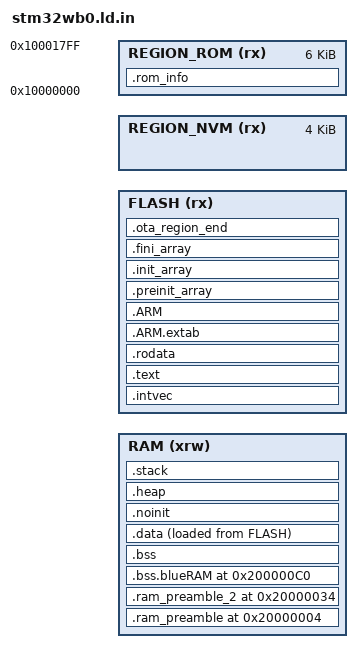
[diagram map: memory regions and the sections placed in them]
ENTRY(Reset_Handler)

_Min_Heap_Size = @min_heap_size@;
_Min_Stack_Size = @min_stack_size@;

_MEMORY_RAM_BEGIN_ = @ram_origin@;
_MEMORY_RAM_SIZE_ = @ram_length@;
_MEMORY_FLASH_BEGIN_ = @flash_origin@;
_MEMORY_FLASH_SIZE_ = @flash_length@;
_MEMORY_ROM_BEGIN_ = 0x10000000;
_MEMORY_ROM_SIZE_ = 0x1800;
FLASH_NVM_DATASIZE = 4K;

MEMORY
{
  RAM (xrw)       : ORIGIN = _MEMORY_RAM_BEGIN_, LENGTH = _MEMORY_RAM_SIZE_
  FLASH (rx)      : ORIGIN = _MEMORY_FLASH_BEGIN_, LENGTH = _MEMORY_FLASH_SIZE_ - FLASH_NVM_DATASIZE
  REGION_NVM (rx) : ORIGIN = _MEMORY_FLASH_BEGIN_ + _MEMORY_FLASH_SIZE_ - FLASH_NVM_DATASIZE, LENGTH = FLASH_NVM_DATASIZE
  REGION_ROM (rx) : ORIGIN = _MEMORY_ROM_BEGIN_, LENGTH = _MEMORY_ROM_SIZE_
}

SECTIONS
{
  .intvec (ORIGIN(FLASH)) :
  {
    . = ALIGN(4);
    KEEP(*(.intvec))
    . = ALIGN(4);
  } >FLASH

  .text :
  {
    . = ALIGN(4);
    KEEP(*(TAG_OTA_START))
    *(.text)
    *(.text*)
    *(.glue_7)
    *(.glue_7t)
    *(.eh_frame)
    KEEP(*(.cmd_call_table))
    KEEP(*(.init))
    KEEP(*(.fini))
    . = ALIGN(4);
    _etext = .;
  } >FLASH

  .rodata :
  {
    . = ALIGN(4);
    *(.rodata)
    *(.rodata*)
    . = ALIGN(4);
  } >FLASH

  .ARM.extab : { *(.ARM.extab* .gnu.linkonce.armextab.*) } >FLASH
  .ARM :
  {
    __exidx_start = .;
    *(.ARM.exidx*)
    __exidx_end = .;
  } >FLASH

  .preinit_array :
  {
    PROVIDE_HIDDEN (__preinit_array_start = .);
    KEEP (*(.preinit_array*))
    PROVIDE_HIDDEN (__preinit_array_end = .);
  } >FLASH
  .init_array :
  {
    PROVIDE_HIDDEN (__init_array_start = .);
    KEEP (*(SORT(.init_array.*)))
    KEEP (*(.init_array*))
    PROVIDE_HIDDEN (__init_array_end = .);
  } >FLASH
  .fini_array :
  {
    PROVIDE_HIDDEN (__fini_array_start = .);
    KEEP (*(SORT(.fini_array.*)))
    KEEP (*(.fini_array*))
    PROVIDE_HIDDEN (__fini_array_end = .);
  } >FLASH

  _sidata = LOADADDR(.data);

  .ram_preamble 0x20000004 (NOLOAD) :
  {
    KEEP(*(.ram_vr))
  } >RAM

  .ram_preamble_2 0x20000034 (NOLOAD) :
  {
    KEEP(*(.crash_info_ram_vr))
  } >RAM

  .bss.blueRAM 0x200000C0 :
  {
    . = ALIGN(4);
    _sbssblue = .;
    KEEP(*(.bss.__blue_RAM))
    . = ALIGN(4);
    _ebssblue = .;
  } >RAM

  .bss :
  {
    . = ALIGN(4);
    _sbss = .;
    __bss_start__ = _sbss;
    *(.bss)
    *(.bss*)
    *(COMMON)
    . = ALIGN(4);
    _ebss = .;
    __bss_end__ = _ebss;
  } >RAM

  .data :
  {
    . = ALIGN(4);
    _sdata = .;
    *(.data)
    *(.data*)
    . = ALIGN(4);
    _edata = .;
  } >RAM AT> FLASH

  .noinit (NOLOAD) :
  {
    . = ALIGN(4);
    *(.noinit)
    *(.noinit*)
    . = ALIGN(4);
  } >RAM

  .ota_region_end :
  {
    . = ALIGN(4);
    KEEP(*(TAG_OTA_END))
    . = ALIGN(4);
  } >FLASH

  .heap (NOLOAD) :
  {
    . = ALIGN(4);
    PROVIDE ( end = . );
    PROVIDE ( _end = . );
    . = . + _Min_Heap_Size;
    . = ALIGN(4);
  } >RAM

  .stack (ORIGIN(RAM) + LENGTH(RAM) - _Min_Stack_Size) (NOLOAD) :
  {
    . = ALIGN(4);
    . = . + _Min_Stack_Size;
    . = ALIGN(4);
    _estack = .;
  } >RAM

  .rom_info (NOLOAD) :
  {
    . = ALIGN(4);
    KEEP(*(.rom_info))
    . = ALIGN(4);
  } >REGION_ROM

  /DISCARD/ :
  {
    libc.a ( * )
    libm.a ( * )
    libgcc.a ( * )
  }

  .ARM.attributes 0 : { *(.ARM.attributes) }
}
